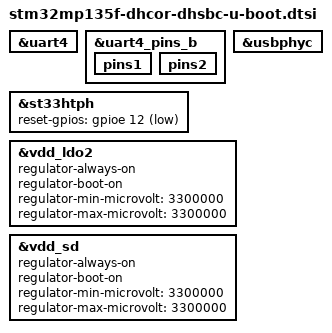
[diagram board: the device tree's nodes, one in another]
// SPDX-License-Identifier: (GPL-2.0+ OR BSD-3-Clause)
/*
 * Copyright (C) 2024 Marek Vasut <marex@denx.de>
 */

#include "stm32mp13xx-dhcor-u-boot.dtsi"

&uart4 {
	bootph-all;
};

&uart4_pins_b {
	bootph-all;

	pins1 {
		bootph-all;
	};
	pins2 {
		bootph-all;
	};
};

&usbphyc {
	bootph-all;
};

&st33htph {
	reset-gpios = <&gpioe 12 GPIO_ACTIVE_LOW>;
};

/* LDO2 is expansion connector 3V3 supply on STM32MP13xx DHCOR DHSBC rev.200 */
&vdd_ldo2 {
	bootph-all;
	regulator-always-on;
	regulator-boot-on;
	regulator-min-microvolt = <3300000>;
	regulator-max-microvolt = <3300000>;
};

/* LDO5 is carrier board 3V3 supply on STM32MP13xx DHCOR DHSBC rev.200 */
&vdd_sd {
	bootph-all;
	regulator-always-on;
	regulator-boot-on;
	regulator-min-microvolt = <3300000>;
	regulator-max-microvolt = <3300000>;
};
